# STM32WB07 register map
File version: 0.4
CPU: CM0+ r0p0, little endian, MPU, no FPU, 2 interrupt priority bits
Registers are 32-bit, read-write, reset 0x0 unless marked. A register's access mark holds for its fields unless they carry their own. Offsets are from the block's base; [hi:lo] are bit positions.

## PKA
Base 0x48300000
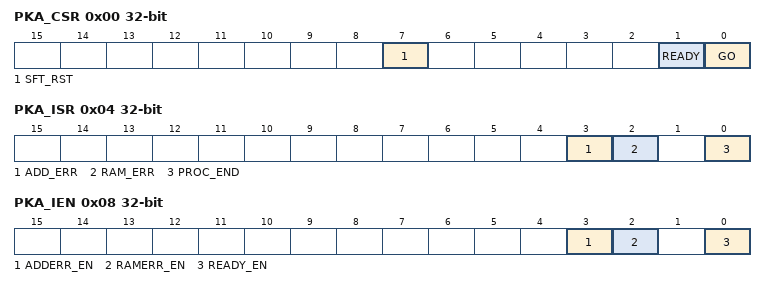
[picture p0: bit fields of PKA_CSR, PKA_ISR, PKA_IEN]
0x00 PKA_CSR
  [7] SFT_RST — PKA software reset. Writing 0 clears the bit and releases the PKA block reset. Writing 1 resets the PKA block. The PKA RAM content is not changed.
  [1] READY ro — PKA readiness status. 0: The PKA is still computing 1: The PKA is ready to start a new calculation
  [0] GO — PKA start processing command. Writing 0 has no effect Writing 1 starts the encryption engine
0x04 PKA_ISR
  [3] ADD_ERR — AHB Address error interrupt.
  [2] RAM_ERR — RAM read / write access error interrupt.
  [0] PROC_END — PKA process ending interrupt. When read: 0: No new event detected 1: The PKA process is ended (This bit is set to 1 when the PKA_CSR.READY bit rises.) When written: To clear the pending interrupt, the user must write this bit to 1 and clear it just after by writing 0. If the write 0 does not occur, the interrupt is generated on next event towards the CPU if enabled in PKA_IER but the flag is seen at 0 when the interrupt handler reads it in this register (as clear action is still active).
0x08 PKA_IEN
  [3] ADDERR_EN — AHB Address error interrupt enable.
  [2] RAMERR_EN — RAM access error interrupt enable.
  [0] READY_EN — READY interrupt enable.

## IWDG
Base 0x40003000
0x00 IWDG_KR
  [15:0] KEY wo — Key value. Software can only write these bits. Reading returns the reset value. These bits must be written by software at regular intervals with the key value 0xAAAA, otherwise the watchdog generates a reset when the counter reaches 0. Writing the key value 0x5555 to enables access to the IWDG_PR, IWDG_RLR and IWDG_WINR registers. Writing the key value CCCCh starts the watchdog
0x04 IWDG_PR
  [2:0] PR — Prescaler divider. Set and reset by software. These bits are write access protected. They are written by software to select the prescaler divider feeding the counter clock. PVU bit of IWDG_SR must be reset in order to be able to change the prescaler divider. 000: divider/4 001: divider/8 010: divider/16 011: divider/32 100: divider/64 101: divider/128 110: divider/256 111: divider/256
0x08 IWDG_RLR reset 0xFFF
  [11:0] RL — Watchdog counter reload value. Set and reset by software. These bits are write access protected. They are written by software to define the value to be loaded in the watchdog counter each time the value 0xAAAA is written in the IWDG_KR register. The watchdog counter counts down from this value. The timeout period is a function of this value and the clock prescaler. The RVU bit in the IWDG_SR register must be reset in order to be able to change the reload value.
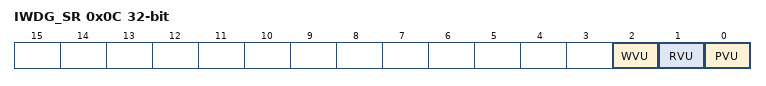
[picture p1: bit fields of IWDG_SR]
0x0C IWDG_SR ro
  [2] WVU — Watchdog counter window value update. Read only bit. This bit is set by hardware to indicate that an update of the window value is ongoing. It is reset by hardware when the reload value update operation is completed in the VDD voltage domain (takes up to 5 RC 40 kHz cycles). Window value can be updated only when WVU bit is reset. This bit is generated only if generic window = 1
  [1] RVU — Watchdog counter reload value update. Read only bit. This bit is set by hardware to indicate that an update of the reload value is ongoing. It is reset by hardware when the reload value update operation is completed in the VDD voltage domain (takes up to 5 RC 40 kHz cycles). Reload value can be updated only when RVU bit is reset
  [0] PVU — Watchdog prescaler value update. Read only bit. This bit is set by hardware to indicate that an update of the prescaler value is ongoing. It is reset by hardware when the prescaler update operation is completed in the VDD voltage domain (takes up to 5 RC 40 kHz cycles). Prescaler value can be updated only when PVU bit is reset
0x10 IWDG_WINR
  [11:0] WIN — Watchdog counter window value. Set and reset by software. These bits are write access protected. These bits contain the high limit of the window value to be compared to the downcounter. To prevent a reset, the downcounter must be reloaded when its value is lower than the window register value and greater than 0x0 The WVU bit in the IWDG_SR register must be reset in order to be able to change the reload value.
